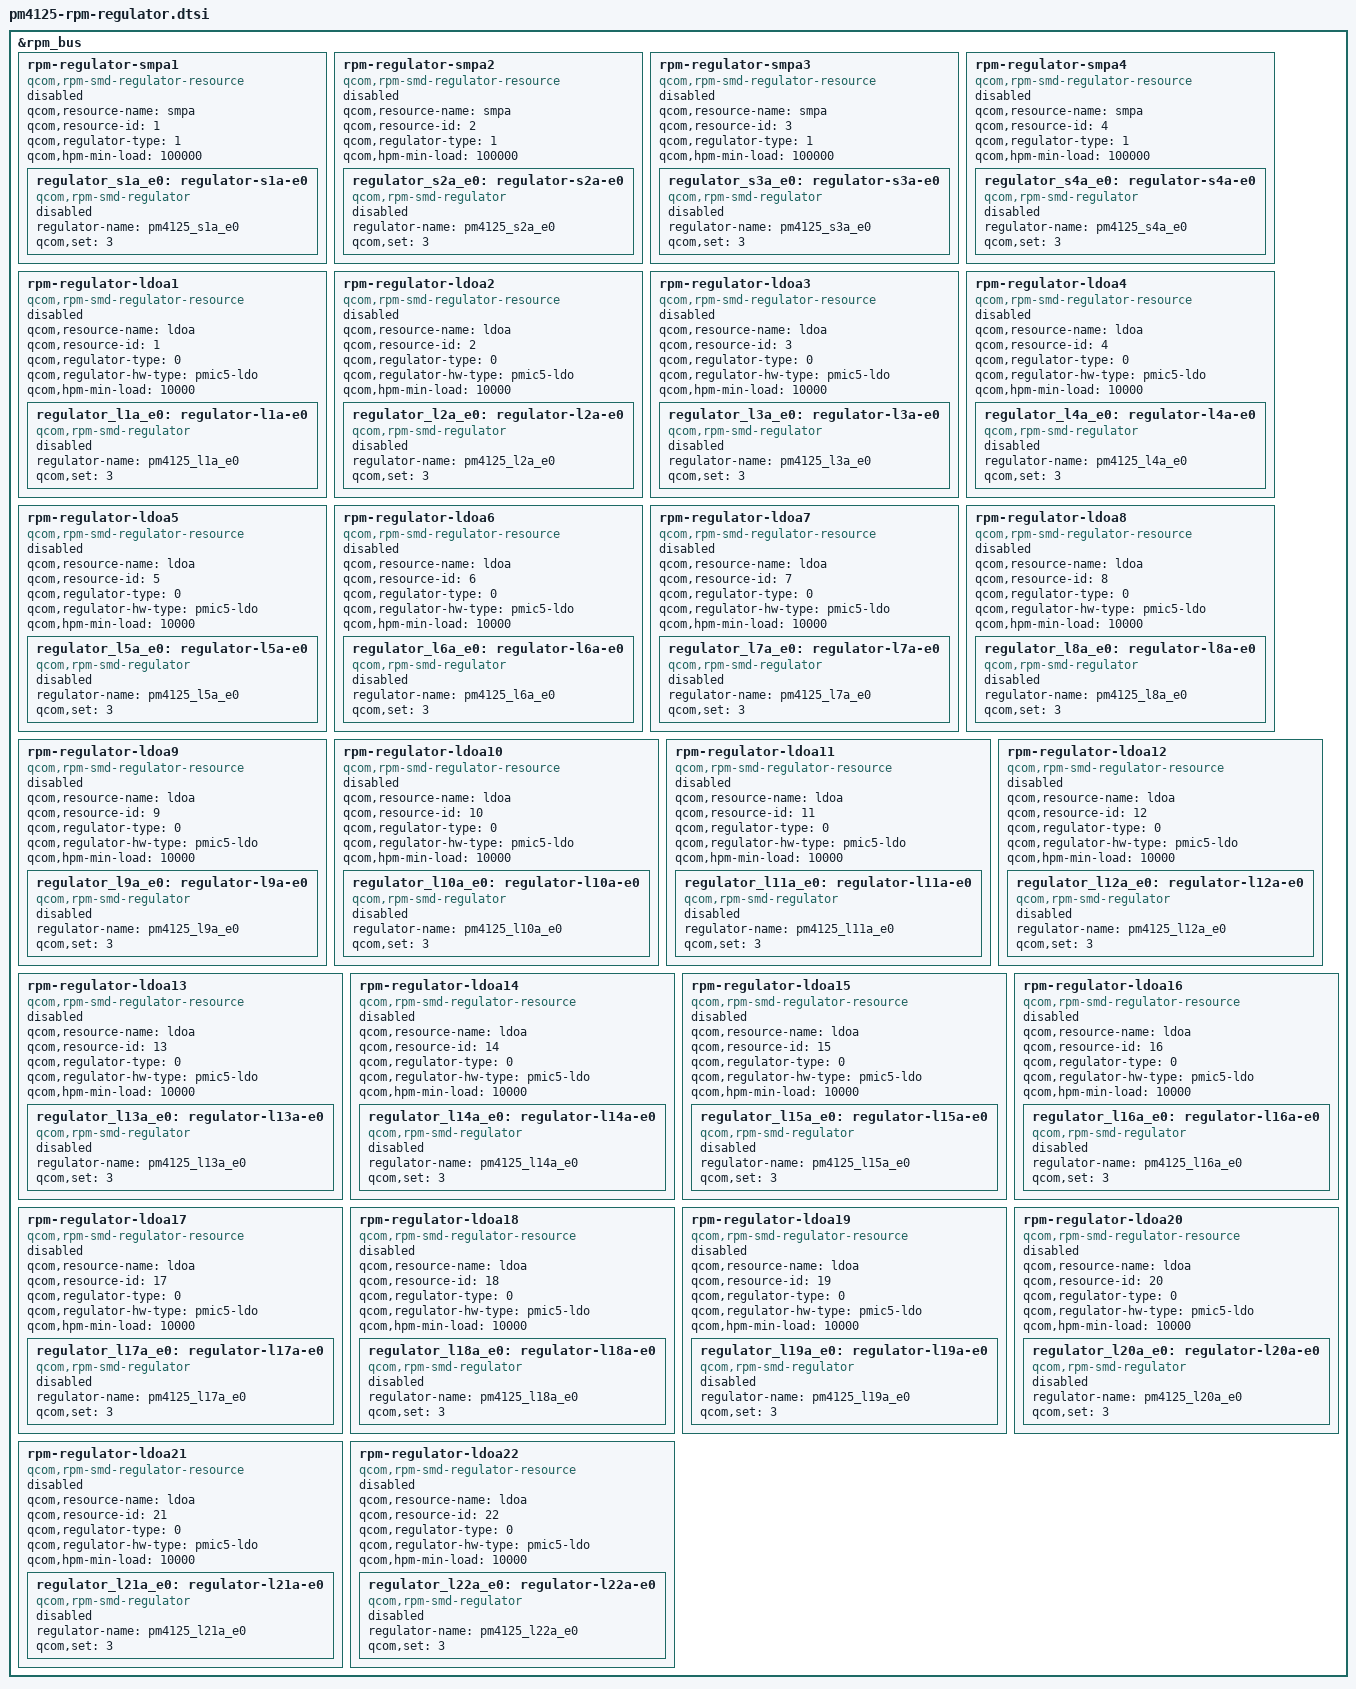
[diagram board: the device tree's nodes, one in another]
// SPDX-License-Identifier: BSD-3-Clause
/*
 * Copyright (c) Qualcomm Technologies, Inc. and/or its subsidiaries.
 */

&rpm_bus {
	/* SMPS Regulators - PM4125 */
	rpm-regulator-smpa1 {
		compatible = "qcom,rpm-smd-regulator-resource";
		qcom,resource-name = "smpa";
		qcom,resource-id = <1>;
		qcom,regulator-type = <1>;
		qcom,hpm-min-load = <100000>;
		status = "disabled";

		regulator_s1a_e0: regulator-s1a-e0 {
			compatible = "qcom,rpm-smd-regulator";
			regulator-name = "pm4125_s1a_e0";
			qcom,set = <3>;
			status = "disabled";
		};
	};

	rpm-regulator-smpa2 {
		compatible = "qcom,rpm-smd-regulator-resource";
		qcom,resource-name = "smpa";
		qcom,resource-id = <2>;
		qcom,regulator-type = <1>;
		qcom,hpm-min-load = <100000>;
		status = "disabled";

		regulator_s2a_e0: regulator-s2a-e0 {
			compatible = "qcom,rpm-smd-regulator";
			regulator-name = "pm4125_s2a_e0";
			qcom,set = <3>;
			status = "disabled";
		};
	};

	rpm-regulator-smpa3 {
		compatible = "qcom,rpm-smd-regulator-resource";
		qcom,resource-name = "smpa";
		qcom,resource-id = <3>;
		qcom,regulator-type = <1>;
		qcom,hpm-min-load = <100000>;
		status = "disabled";

		regulator_s3a_e0: regulator-s3a-e0 {
			compatible = "qcom,rpm-smd-regulator";
			regulator-name = "pm4125_s3a_e0";
			qcom,set = <3>;
			status = "disabled";
		};
	};

	rpm-regulator-smpa4 {
		compatible = "qcom,rpm-smd-regulator-resource";
		qcom,resource-name = "smpa";
		qcom,resource-id = <4>;
		qcom,regulator-type = <1>;
		qcom,hpm-min-load = <100000>;
		status = "disabled";

		regulator_s4a_e0: regulator-s4a-e0 {
			compatible = "qcom,rpm-smd-regulator";
			regulator-name = "pm4125_s4a_e0";
			qcom,set = <3>;
			status = "disabled";
		};
	};

	/* LDO Regulators - PM4125 */
	rpm-regulator-ldoa1 {
		compatible = "qcom,rpm-smd-regulator-resource";
		qcom,resource-name = "ldoa";
		qcom,resource-id = <1>;
		qcom,regulator-type = <0>;
		qcom,regulator-hw-type = "pmic5-ldo";
		qcom,hpm-min-load = <10000>;
		status = "disabled";

		regulator_l1a_e0: regulator-l1a-e0 {
			compatible = "qcom,rpm-smd-regulator";
			regulator-name = "pm4125_l1a_e0";
			qcom,set = <3>;
			status = "disabled";
		};
	};

	rpm-regulator-ldoa2 {
		compatible = "qcom,rpm-smd-regulator-resource";
		qcom,resource-name = "ldoa";
		qcom,resource-id = <2>;
		qcom,regulator-type = <0>;
		qcom,regulator-hw-type = "pmic5-ldo";
		qcom,hpm-min-load = <10000>;
		status = "disabled";

		regulator_l2a_e0: regulator-l2a-e0 {
			compatible = "qcom,rpm-smd-regulator";
			regulator-name = "pm4125_l2a_e0";
			qcom,set = <3>;
			status = "disabled";
		};
	};

	rpm-regulator-ldoa3 {
		compatible = "qcom,rpm-smd-regulator-resource";
		qcom,resource-name = "ldoa";
		qcom,resource-id = <3>;
		qcom,regulator-type = <0>;
		qcom,regulator-hw-type = "pmic5-ldo";
		qcom,hpm-min-load = <10000>;
		status = "disabled";

		regulator_l3a_e0: regulator-l3a-e0 {
			compatible = "qcom,rpm-smd-regulator";
			regulator-name = "pm4125_l3a_e0";
			qcom,set = <3>;
			status = "disabled";
		};
	};

	rpm-regulator-ldoa4 {
		compatible = "qcom,rpm-smd-regulator-resource";
		qcom,resource-name = "ldoa";
		qcom,resource-id = <4>;
		qcom,regulator-type = <0>;
		qcom,regulator-hw-type = "pmic5-ldo";
		qcom,hpm-min-load = <10000>;
		status = "disabled";

		regulator_l4a_e0: regulator-l4a-e0 {
			compatible = "qcom,rpm-smd-regulator";
			regulator-name = "pm4125_l4a_e0";
			qcom,set = <3>;
			status = "disabled";
		};
	};

	rpm-regulator-ldoa5 {
		compatible = "qcom,rpm-smd-regulator-resource";
		qcom,resource-name = "ldoa";
		qcom,resource-id = <5>;
		qcom,regulator-type = <0>;
		qcom,regulator-hw-type = "pmic5-ldo";
		qcom,hpm-min-load = <10000>;
		status = "disabled";

		regulator_l5a_e0: regulator-l5a-e0 {
			compatible = "qcom,rpm-smd-regulator";
			regulator-name = "pm4125_l5a_e0";
			qcom,set = <3>;
			status = "disabled";
		};
	};

	rpm-regulator-ldoa6 {
		compatible = "qcom,rpm-smd-regulator-resource";
		qcom,resource-name = "ldoa";
		qcom,resource-id = <6>;
		qcom,regulator-type = <0>;
		qcom,regulator-hw-type = "pmic5-ldo";
		qcom,hpm-min-load = <10000>;
		status = "disabled";

		regulator_l6a_e0: regulator-l6a-e0 {
			compatible = "qcom,rpm-smd-regulator";
			regulator-name = "pm4125_l6a_e0";
			qcom,set = <3>;
			status = "disabled";
		};
	};

	rpm-regulator-ldoa7 {
		compatible = "qcom,rpm-smd-regulator-resource";
		qcom,resource-name = "ldoa";
		qcom,resource-id = <7>;
		qcom,regulator-type = <0>;
		qcom,regulator-hw-type = "pmic5-ldo";
		qcom,hpm-min-load = <10000>;
		status = "disabled";

		regulator_l7a_e0: regulator-l7a-e0 {
			compatible = "qcom,rpm-smd-regulator";
			regulator-name = "pm4125_l7a_e0";
			qcom,set = <3>;
			status = "disabled";
		};
	};

	rpm-regulator-ldoa8 {
		compatible = "qcom,rpm-smd-regulator-resource";
		qcom,resource-name = "ldoa";
		qcom,resource-id = <8>;
		qcom,regulator-type = <0>;
		qcom,regulator-hw-type = "pmic5-ldo";
		qcom,hpm-min-load = <10000>;
		status = "disabled";

		regulator_l8a_e0: regulator-l8a-e0 {
			compatible = "qcom,rpm-smd-regulator";
			regulator-name = "pm4125_l8a_e0";
			qcom,set = <3>;
			status = "disabled";
		};
	};

	rpm-regulator-ldoa9 {
		compatible = "qcom,rpm-smd-regulator-resource";
		qcom,resource-name = "ldoa";
		qcom,resource-id = <9>;
		qcom,regulator-type = <0>;
		qcom,regulator-hw-type = "pmic5-ldo";
		qcom,hpm-min-load = <10000>;
		status = "disabled";

		regulator_l9a_e0: regulator-l9a-e0 {
			compatible = "qcom,rpm-smd-regulator";
			regulator-name = "pm4125_l9a_e0";
			qcom,set = <3>;
			status = "disabled";
		};
	};

	rpm-regulator-ldoa10 {
		compatible = "qcom,rpm-smd-regulator-resource";
		qcom,resource-name = "ldoa";
		qcom,resource-id = <10>;
		qcom,regulator-type = <0>;
		qcom,regulator-hw-type = "pmic5-ldo";
		qcom,hpm-min-load = <10000>;
		status = "disabled";

		regulator_l10a_e0: regulator-l10a-e0 {
			compatible = "qcom,rpm-smd-regulator";
			regulator-name = "pm4125_l10a_e0";
			qcom,set = <3>;
			status = "disabled";
		};
	};

	rpm-regulator-ldoa11 {
		compatible = "qcom,rpm-smd-regulator-resource";
		qcom,resource-name = "ldoa";
		qcom,resource-id = <11>;
		qcom,regulator-type = <0>;
		qcom,regulator-hw-type = "pmic5-ldo";
		qcom,hpm-min-load = <10000>;
		status = "disabled";

		regulator_l11a_e0: regulator-l11a-e0 {
			compatible = "qcom,rpm-smd-regulator";
			regulator-name = "pm4125_l11a_e0";
			qcom,set = <3>;
			status = "disabled";
		};
	};

	rpm-regulator-ldoa12 {
		compatible = "qcom,rpm-smd-regulator-resource";
		qcom,resource-name = "ldoa";
		qcom,resource-id = <12>;
		qcom,regulator-type = <0>;
		qcom,regulator-hw-type = "pmic5-ldo";
		qcom,hpm-min-load = <10000>;
		status = "disabled";

		regulator_l12a_e0: regulator-l12a-e0 {
			compatible = "qcom,rpm-smd-regulator";
			regulator-name = "pm4125_l12a_e0";
			qcom,set = <3>;
			status = "disabled";
		};
	};

	rpm-regulator-ldoa13 {
		compatible = "qcom,rpm-smd-regulator-resource";
		qcom,resource-name = "ldoa";
		qcom,resource-id = <13>;
		qcom,regulator-type = <0>;
		qcom,regulator-hw-type = "pmic5-ldo";
		qcom,hpm-min-load = <10000>;
		status = "disabled";

		regulator_l13a_e0: regulator-l13a-e0 {
			compatible = "qcom,rpm-smd-regulator";
			regulator-name = "pm4125_l13a_e0";
			qcom,set = <3>;
			status = "disabled";
		};
	};

	rpm-regulator-ldoa14 {
		compatible = "qcom,rpm-smd-regulator-resource";
		qcom,resource-name = "ldoa";
		qcom,resource-id = <14>;
		qcom,regulator-type = <0>;
		qcom,regulator-hw-type = "pmic5-ldo";
		qcom,hpm-min-load = <10000>;
		status = "disabled";

		regulator_l14a_e0: regulator-l14a-e0 {
			compatible = "qcom,rpm-smd-regulator";
			regulator-name = "pm4125_l14a_e0";
			qcom,set = <3>;
			status = "disabled";
		};
	};

	rpm-regulator-ldoa15 {
		compatible = "qcom,rpm-smd-regulator-resource";
		qcom,resource-name = "ldoa";
		qcom,resource-id = <15>;
		qcom,regulator-type = <0>;
		qcom,regulator-hw-type = "pmic5-ldo";
		qcom,hpm-min-load = <10000>;
		status = "disabled";

		regulator_l15a_e0: regulator-l15a-e0 {
			compatible = "qcom,rpm-smd-regulator";
			regulator-name = "pm4125_l15a_e0";
			qcom,set = <3>;
			status = "disabled";
		};
	};

	rpm-regulator-ldoa16 {
		compatible = "qcom,rpm-smd-regulator-resource";
		qcom,resource-name = "ldoa";
		qcom,resource-id = <16>;
		qcom,regulator-type = <0>;
		qcom,regulator-hw-type = "pmic5-ldo";
		qcom,hpm-min-load = <10000>;
		status = "disabled";

		regulator_l16a_e0: regulator-l16a-e0 {
			compatible = "qcom,rpm-smd-regulator";
			regulator-name = "pm4125_l16a_e0";
			qcom,set = <3>;
			status = "disabled";
		};
	};

	rpm-regulator-ldoa17 {
		compatible = "qcom,rpm-smd-regulator-resource";
		qcom,resource-name = "ldoa";
		qcom,resource-id = <17>;
		qcom,regulator-type = <0>;
		qcom,regulator-hw-type = "pmic5-ldo";
		qcom,hpm-min-load = <10000>;
		status = "disabled";

		regulator_l17a_e0: regulator-l17a-e0 {
			compatible = "qcom,rpm-smd-regulator";
			regulator-name = "pm4125_l17a_e0";
			qcom,set = <3>;
			status = "disabled";
		};
	};

	rpm-regulator-ldoa18 {
		compatible = "qcom,rpm-smd-regulator-resource";
		qcom,resource-name = "ldoa";
		qcom,resource-id = <18>;
		qcom,regulator-type = <0>;
		qcom,regulator-hw-type = "pmic5-ldo";
		qcom,hpm-min-load = <10000>;
		status = "disabled";

		regulator_l18a_e0: regulator-l18a-e0 {
			compatible = "qcom,rpm-smd-regulator";
			regulator-name = "pm4125_l18a_e0";
			qcom,set = <3>;
			status = "disabled";
		};
	};

	rpm-regulator-ldoa19 {
		compatible = "qcom,rpm-smd-regulator-resource";
		qcom,resource-name = "ldoa";
		qcom,resource-id = <19>;
		qcom,regulator-type = <0>;
		qcom,regulator-hw-type = "pmic5-ldo";
		qcom,hpm-min-load = <10000>;
		status = "disabled";

		regulator_l19a_e0: regulator-l19a-e0 {
			compatible = "qcom,rpm-smd-regulator";
			regulator-name = "pm4125_l19a_e0";
			qcom,set = <3>;
			status = "disabled";
		};
	};

	rpm-regulator-ldoa20 {
		compatible = "qcom,rpm-smd-regulator-resource";
		qcom,resource-name = "ldoa";
		qcom,resource-id = <20>;
		qcom,regulator-type = <0>;
		qcom,regulator-hw-type = "pmic5-ldo";
		qcom,hpm-min-load = <10000>;
		status = "disabled";

		regulator_l20a_e0: regulator-l20a-e0 {
			compatible = "qcom,rpm-smd-regulator";
			regulator-name = "pm4125_l20a_e0";
			qcom,set = <3>;
			status = "disabled";
		};
	};

	rpm-regulator-ldoa21 {
		compatible = "qcom,rpm-smd-regulator-resource";
		qcom,resource-name = "ldoa";
		qcom,resource-id = <21>;
		qcom,regulator-type = <0>;
		qcom,regulator-hw-type = "pmic5-ldo";
		qcom,hpm-min-load = <10000>;
		status = "disabled";

		regulator_l21a_e0: regulator-l21a-e0 {
			compatible = "qcom,rpm-smd-regulator";
			regulator-name = "pm4125_l21a_e0";
			qcom,set = <3>;
			status = "disabled";
		};
	};

	rpm-regulator-ldoa22 {
		compatible = "qcom,rpm-smd-regulator-resource";
		qcom,resource-name = "ldoa";
		qcom,resource-id = <22>;
		qcom,regulator-type = <0>;
		qcom,regulator-hw-type = "pmic5-ldo";
		qcom,hpm-min-load = <10000>;
		status = "disabled";

		regulator_l22a_e0: regulator-l22a-e0 {
			compatible = "qcom,rpm-smd-regulator";
			regulator-name = "pm4125_l22a_e0";
			qcom,set = <3>;
			status = "disabled";
		};
	};
};
